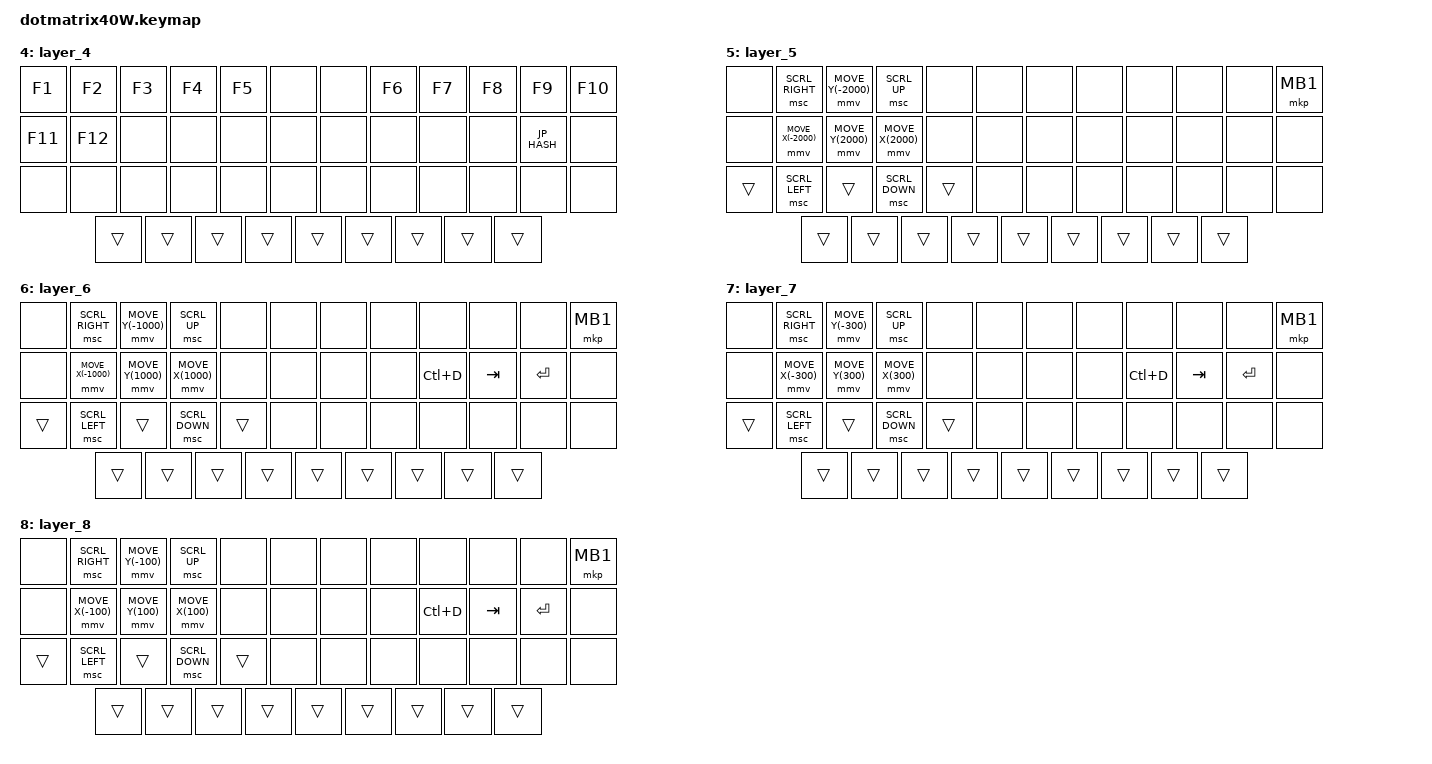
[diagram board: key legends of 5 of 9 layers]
/*
 * Copyright (c) 2021 Nick Winans
 *
 * SPDX-License-Identifier: MIT
 */

#include "keycode_japanese.h"

#include <behaviors.dtsi>
#include <dt-bindings/zmk/backlight.h>
#include <dt-bindings/zmk/bt.h>
#include <dt-bindings/zmk/keys.h>
#include <dt-bindings/zmk/pointing.h>

// JIS layout fixes for Japanese OS settings
#define JP_DQUOTE       AT                // "
#define JP_AMPERSAND    CARET             // &
#define JP_QUOTE        AMPERSAND         // '
#define JP_EQUAL        UNDER             // =
#define JP_CARET        EQUAL             // ^
#define JP_YEN          0x89              // ¥
#define JP_PLUS         COLON             // +
#define JP_TILDE        PLUS              // ~
#define JP_PIPE         LS(0x89)          // |
#define JP_AT           LEFT_BRACKET      // @
#define JP_COLON        SINGLE_QUOTE      // :
#define JP_ASTERISK     DOUBLE_QUOTES     // *
#define JP_BACKQUOTE    LEFT_BRACE        // `
#define JP_UNDERSCORE   LS(0x87)          // _
#define JP_LBRACKET     RIGHT_BRACKET     // [
#define JP_RBRACKET     BACKSLASH         // ]
#define JP_LPAREN       ASTERISK          // (
#define JP_RPAREN       LEFT_PARENTHESIS  // )
#define JP_LBRACE       RIGHT_BRACE       // {
#define JP_RBRACE       PIPE              // }
#define JP_KANA         LANGUAGE_1        // Kana
#define JP_EISU         LANGUAGE_2        // Eisu
#define JP_HANZEN       GRAVE             // Han/Zen
#define JP_BSLH         INT1              // Backslash



#define ZMK_POINTING_DEFAULT_SCRL_VAL 40

// Custom scroll values to ensure a single encoder click produces enough velocity

#define SCRL_UP_FAST   MOVE_Y(35)
#define SCRL_DOWN_FAST MOVE_Y(-35)
#define SCRL_LEFT_FAST MOVE_X(-35)
#define SCRL_RIGHT_FAST MOVE_X(35)

&mmv {
    time-to-max-speed-ms = <0>;
    acceleration-exponent = <0>;
    trigger-period-ms = <10>;
    delay-ms = <0>;
};

&mt { 
    flavor = "balanced"; 
    tapping-term-ms = <200>;
    quick-tap-ms = <150>; 
};

&lt {
    flavor = "balanced";
    tapping-term-ms = <200>; 
    quick-tap-ms = <150>; 
};




    // 0  1  2  3  4  5  6  7  8  9  10 11
    // 12_13_14_15_16_17_18_19_20_21_22_23
    // 24 25 26 27 28 29 30 31 32 33 34 35
    // 36 37 38 39 40       41 42 43 44 45




/ {
    combos {
        compatible = "zmk,combos";

      lang {
            bindings = <&kp GRAVE>;
            key-positions = <1 3>;
            layers = <0>;
            timeout-ms = <200>;
        };

        fopen {
            bindings = <&kp LG(N2)>;
            key-positions = <7 11>;
            layers = <0>;
            timeout-ms = <200>;
        };


       bootloader {
            bindings = <&bootloader>;
            key-positions = <0 11 36 45>;
            timeout-ms = <200>;
        };

        eq {
            bindings = <&bt BT_CLR_ALL>;
            key-positions = <0 12 24>;
            timeout-ms = <50>;
            layers = <0>;
        };

        bt0 {
            bindings = <&bt BT_SEL 0>;
            key-positions = <7 19 31>;
            timeout-ms = <50>;
            layers = <0>;
        };

        bt1 {
            bindings = <&bt BT_SEL 1>;
            key-positions = <8 20 32>;
            layers = <0>;
        };

        bt2 {
            bindings = <&bt BT_SEL 2>;
            key-positions = <9 21 33>;
            layers = <0>;
        };

        mute {
            bindings = <&kp C_MUTE>;
            key-positions = <15 16>;
            layers = <0>;
        };

        vup {
            bindings = <&kp C_VOL_UP>;
            key-positions = <3 4>;
            layers = <0>;
        };

        vdn {
            bindings = <&kp C_VOL_DN>;
            key-positions = <27 28>;
            layers = <0>;
        };

        printscreen {
            bindings = <&kp PSCRN>;
            key-positions = <25 27>;
            layers = <0>;
        };


        space {
            bindings = <&kp SPACE>;
            key-positions = <12 15>;
            layers = <0>;
        };
};

};






/ {
    behaviors {
        encoder_scroll_v: encoder_scroll_v {
            compatible = "zmk,behavior-sensor-rotate";
            #sensor-binding-cells = <0>;
            bindings = <&msc SCRL_DOWN_FAST>, <&msc SCRL_UP_FAST>;

            tap-ms = <50>;
        };

        encoder_scroll_h: encoder_scroll_h {
            compatible = "zmk,behavior-sensor-rotate";
            #sensor-binding-cells = <0>;
            bindings = <&msc SCRL_RIGHT_FAST>, <&msc SCRL_LEFT_FAST>;

            tap-ms = <50>;
        };

        encoder_backlight: encoder_backlight {
            compatible = "zmk,behavior-sensor-rotate";
            #sensor-binding-cells = <0>;
            bindings = <&bl BL_INC>, <&bl BL_DEC>;
        };

        encoder_arrow_v: encoder_arrow_v {
            compatible = "zmk,behavior-sensor-rotate";
            #sensor-binding-cells = <0>;
            bindings = <&kp DOWN>, <&kp UP>;
        };

        encoder_arrow_h: encoder_arrow_h {
            compatible = "zmk,behavior-sensor-rotate";
            #sensor-binding-cells = <0>;
            bindings = <&kp RIGHT>, <&kp LEFT>;
        };

        encoder_volume: encoder_volume {
            compatible = "zmk,behavior-sensor-rotate";
            #sensor-binding-cells = <0>;
            bindings = <&kp C_VOL_UP>, <&kp C_VOL_DN>;
        };

        encoder_undo_win: encoder_undo_win {
            compatible = "zmk,behavior-sensor-rotate";
            #sensor-binding-cells = <0>;
            bindings = <&kp LC(Y)>, <&kp LC(Z)>;
        };

        encoder_undo_mac: encoder_undo_mac {
            compatible = "zmk,behavior-sensor-rotate";
            #sensor-binding-cells = <0>;
            bindings = <&kp LG(LS(Z))>, <&kp LG(Z)>;
        };

        mo2: mo2 {
            compatible = "zmk,behavior-mod-morph";
            #binding-cells = <0>;
            bindings = <&kp N2>, <&kp JP_DQUOTE>;

            mods = <(MOD_LSFT|MOD_RSFT)>;
        };

        mo6: mo6 {
            compatible = "zmk,behavior-mod-morph";
            #binding-cells = <0>;
            bindings = <&kp N6>, <&kp JP_AMPERSAND>;

            mods = <(MOD_LSFT|MOD_RSFT)>;
        };

        mo7: mo7 {
            compatible = "zmk,behavior-mod-morph";
            #binding-cells = <0>;
            bindings = <&kp N7>, <&kp JP_QUOTE>;

            mods = <(MOD_LSFT|MOD_RSFT)>;
        };

        mo8: mo8 {
            compatible = "zmk,behavior-mod-morph";
            #binding-cells = <0>;
            bindings = <&kp N8>, <&kp JP_LPAREN>;

            mods = <(MOD_LSFT|MOD_RSFT)>;
        };

        mo9: mo9 {
            compatible = "zmk,behavior-mod-morph";
            #binding-cells = <0>;
            bindings = <&kp N9>, <&kp JP_RPAREN>;

            mods = <(MOD_LSFT|MOD_RSFT)>;
        };

        mo0: mo0 {
            compatible = "zmk,behavior-mod-morph";
            #binding-cells = <0>;
            bindings = <&kp N0>, <&none>;

            mods = <(MOD_LSFT|MOD_RSFT)>;
        };

        moA: moA {
            compatible = "zmk,behavior-mod-morph";
            #binding-cells = <0>;
            bindings = <&kp MINUS>, <&kp JP_EQUAL>;

            mods = <(MOD_LSFT|MOD_RSFT)>;
        };

        moB: moB {
            compatible = "zmk,behavior-mod-morph";
            #binding-cells = <0>;
            bindings = <&kp JP_CARET>, <&kp JP_TILDE>;

            mods = <(MOD_LSFT|MOD_RSFT)>;
        };

        moC: moC {
            compatible = "zmk,behavior-mod-morph";
            #binding-cells = <0>;
            bindings = <&kp INT3>, <&kp JP_PIPE>;

            mods = <(MOD_LSFT|MOD_RSFT)>;
        };

        moD: moD {
            compatible = "zmk,behavior-mod-morph";
            #binding-cells = <0>;
            bindings = <&kp JP_AT>, <&kp JP_BACKQUOTE>;

            mods = <(MOD_LSFT|MOD_RSFT)>;
        };

        moE: moE {
            compatible = "zmk,behavior-mod-morph";
            #binding-cells = <0>;
            bindings = <&kp JP_LBRACKET>, <&kp JP_LBRACE>;

            mods = <(MOD_LSFT|MOD_RSFT)>;
        };

        moF: moF {
            compatible = "zmk,behavior-mod-morph";
            #binding-cells = <0>;
            bindings = <&kp SEMI>, <&kp KP_PLUS>;

            mods = <(MOD_LSFT|MOD_RSFT)>;
        };

        moG: moG {
            compatible = "zmk,behavior-mod-morph";
            #binding-cells = <0>;
            bindings = <&kp JP_COLON>, <&kp JP_ASTERISK>;

            mods = <(MOD_LSFT|MOD_RSFT)>;
        };

        moH: moH {
            compatible = "zmk,behavior-mod-morph";
            #binding-cells = <0>;
            bindings = <&kp JP_RBRACKET>, <&kp TILDE2>;

            mods = <(MOD_LSFT|MOD_RSFT)>;
        };

        moI: moI {
            compatible = "zmk,behavior-mod-morph";
            #binding-cells = <0>;
            bindings = <&kp JP_BSLH>, <&kp JP_UNDERSCORE>;

            mods = <(MOD_LSFT|MOD_RSFT)>;
        };


        encoder_mouse_v: encoder_mouse_v {
            compatible = "zmk,behavior-sensor-rotate";
            #sensor-binding-cells = <0>;
            bindings = <&mmv MOVE_X(-1500)>, < &mmv MOVE_X(1500)>;

            tap-ms = <50>;
        };



    };


    keymap {
        compatible = "zmk,keymap";

        layer_0 {
            bindings = <

            &kp ESCAPE      &lt 5 Q    &lt 6 E    &lt 7 U     &kp P           &none &none   &lt 8 D        &lt 7 T       &lt 6 R     &lt 5 W     &mkp MB1

            &mt LSHIFT TAB  &lt 3 O    &lt 2 A    &lt 1 I     &mt LCTRL F    &none  &none         &mt RCTRL H  &lt 1 Y       &lt 2 K     &lt 3 S     &mt LEFT_SHIFT B

            &lt 4 MINUS     &mt LGUI X &mt LALT C &mt LSHIFT V  &mt LCTRL L  &kp LC(RG(LEFT))             &kp LG(RC(RIGHT))             &mt RCTRL N  &mt RSHIFT M  &mt RALT G  &mt RGUI J  &lt 4 Z

            &mo 1           &mo 1      &mo 1     &mo 1        &kp LC(RG(LEFT))             &kp LG(RC(RIGHT))          &mo 1      &mo 1      &mo 1         &mo 1
            >;

            sensor-bindings = <&encoder_mouse_v>;
        };

        layer_1 {
 
            bindings = <

            &kp 0x38      &none      &kp UP     &none      &none                         &none &none                    &kp TAB        &kp UP     &kp JP_SQT  &kp JP_DQT  &mkp MB2

          &kp JP_SEMI   &kp LEFT   &kp GRAVE  &kp GRAVE  &kp MINUS                     &none  &none                    &kp BACKSPACE  &kp SPACE  &kp TAB     &kp ENTER   &kp COMMA

            &kp JP_COLON  &none      &none      &none      &none &kp LC(RG(LEFT))             &kp LG(RC(RIGHT))             &kp DELETE     &none      &none       &none       &mt LCTRL PERIOD

            &kp A           &kp A      &kp A      &kp A         &kp A                                                                  &kp A           &kp A      &kp A      &kp A         &kp A
            >;

            sensor-bindings = <&encoder_arrow_h>;
        };

        layer_2 {

            bindings = <

         &none        &kp JP_LT      &kp JP_EQUAL   &kp JP_RT    &kp JP_PRCNT       &none &none                            &kp JP_DLLR   &kp JP_PLUS  &kp JP_CARET      &kp JP_SLASH  &mkp MB3

         &kp JP_LBKT  &kp JP_LPAR    &kp JP_AT      &kp JP_RPAR  &kp JP_RBKT      &none                   &none       &kp JP_QMARK  &kp JP_HASH  &kp DOUBLE_QUOTES &kp LS(0x87)  &kp LS(0x1e)

         &kp JP_TILDE &kp JP_LBRC    &kp JP_AMPS    &kp JP_RBRC  &none            &none                 &none         &kp JP_YEN    &none        &kp JP_SQT        &kp JP_PIPE   &none

            &kp A           &kp A      &kp A      &kp A         &kp A                                                                  &kp A           &kp A      &kp A      &kp A         &kp A
            >;

            sensor-bindings = <&encoder_backlight>;
        };

        layer_3 {
            bindings = <

     &none        &kp HOME   &kp UP     &kp PAGE_UP      &none           &none &none                        &kp TAB          &kp N7          &kp N8        &kp N9         &mkp MB3
                &none        &kp LEFT   &kp DOWN   &kp RIGHT        &none  &none                   &none       &kp BACKSPACE  &kp N4          &mt RGUI N5        &kp N6         &kp ENTER
                &none        &kp END    &none      &kp PAGE_DOWN    &none      &kp TAB             &none           &kp N0         &kp N1          &kp N2        &kp N3         &mt LCTRL PERIOD

            &kp A           &kp A      &kp A      &kp A         &kp A                                                                  &kp A           &kp A      &kp A      &kp A         &kp A
            >;
            sensor-bindings = <&encoder_backlight>;


        };

        layer_4 {
            bindings = <
               &kp F1   &kp F2    &kp F3  &kp F4  &kp F5            &none &none                     &kp F6  &kp F7  &kp F8  &kp F9       &kp F10
               &kp F11  &kp F12   &none   &none   &none     &none                  &none      &none   &none   &none   &kp JP_HASH  &none
               &none    &none     &none   &none   &none     &none                  &none      &none   &none   &none   &none        &none
                &trans  &trans  &trans  &trans  &trans  &trans      &trans  &trans                              &trans
            >;
            sensor-bindings = <&encoder_backlight>;

        };

        layer_5 {
            bindings = <
             &none   &msc SCRL_RIGHT    &mmv MOVE_Y(-2000)  &msc SCRL_UP       &none        &none   &none                     &none   &none  &none  &none  &mkp MB1
                &none   &mmv MOVE_X(-2000) &mmv MOVE_Y(2000)   &mmv MOVE_X(2000)  &none  &none          &none        &none   &none  &none  &none  &none
                &trans  &msc SCRL_LEFT     &trans              &msc SCRL_DOWN     &trans &none          &none        &none   &none  &none  &none  &none
                &trans  &trans  &trans  &trans  &trans  &trans      &trans  &trans                              &trans
            >;
            sensor-bindings = <&encoder_backlight>;

        };

        layer_6 {
            bindings = <
             &none   &msc SCRL_RIGHT    &mmv MOVE_Y(-1000)  &msc SCRL_UP       &none        &none   &none                     &none   &none  &none  &none  &mkp MB1
                &none   &mmv MOVE_X(-1000) &mmv MOVE_Y(1000)   &mmv MOVE_X(1000)  &none  &none          &none        &none  &kp LC(D) &kp TAB  &kp ENTER &none 
                &trans  &msc SCRL_LEFT     &trans              &msc SCRL_DOWN     &trans &none          &none        &none   &none  &none  &none  &none
                &trans  &trans  &trans  &trans  &trans  &trans      &trans  &trans                              &trans
            >;
            sensor-bindings = <&encoder_backlight>;
};

        layer_7 {
            bindings = <
             &none   &msc SCRL_RIGHT    &mmv MOVE_Y(-300)  &msc SCRL_UP       &none        &none   &none                     &none   &none  &none  &none  &mkp MB1
                &none   &mmv MOVE_X(-300) &mmv MOVE_Y(300)   &mmv MOVE_X(300)  &none  &none          &none        &none  &kp LC(D) &kp TAB  &kp ENTER &none 
                &trans  &msc SCRL_LEFT     &trans              &msc SCRL_DOWN     &trans &none          &none        &none   &none  &none  &none  &none
                &trans  &trans  &trans  &trans  &trans  &trans      &trans  &trans                              &trans
            >;
            sensor-bindings = <&encoder_backlight>;

        };

        layer_8 {
            bindings = <
             &none   &msc SCRL_RIGHT    &mmv MOVE_Y(-100)  &msc SCRL_UP       &none        &none   &none                     &none   &none  &none  &none  &mkp MB1
                &none   &mmv MOVE_X(-100) &mmv MOVE_Y(100)   &mmv MOVE_X(100)  &none  &none          &none        &none  &kp LC(D) &kp TAB  &kp ENTER &none 
                &trans  &msc SCRL_LEFT     &trans              &msc SCRL_DOWN     &trans &none          &none        &none   &none  &none  &none  &none
                &trans  &trans  &trans  &trans  &trans  &trans      &trans  &trans                              &trans
            >;
            sensor-bindings = <&encoder_backlight>;

        };






    };
};

// Override msc behavior to remove acceleration and delay for immediate encoder response

&msc {
    acceleration-exponent = <0>;
    time-to-max-speed-ms = <0>;
    delay-ms = <0>;
};

// Special thanks to the following repository for reference and inspiration:
// https://github.com/kureyakey/zmk-config-zonkey

